# VPAC0_COMMON_0_IVPAC_TOP_0_CFG_SLV_PAR_VPAC_VISS0_S_VBUSP_VISS_FCP_CFA_VBUSP_FLEXCFA register map
Vendor: Texas Instruments
Peripheral module from a debugger description file (folder am62A).
Registers are 32-bit, read-write, reset values left out (the file's numbers can be read two ways) unless marked. A register's access mark holds for its fields unless they carry their own. Offsets are as the file gives them; lines under a group give offsets from that group; [hi:lo] are bit positions; {n}, {i} and the like mark numbered series; 'fields as' and 'values as' point back to an identical list; <NAME> marks a mode.

## VPAC0_COMMON_0_IVPAC_TOP_0_CFG_SLV_PAR_VPAC_VISS0_S_VBUSP_VISS_FCP_CFA_VBUSP_FLEXCFA
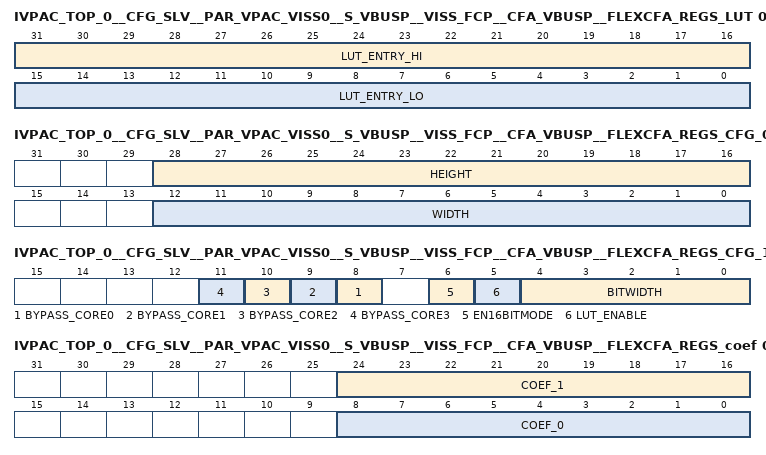
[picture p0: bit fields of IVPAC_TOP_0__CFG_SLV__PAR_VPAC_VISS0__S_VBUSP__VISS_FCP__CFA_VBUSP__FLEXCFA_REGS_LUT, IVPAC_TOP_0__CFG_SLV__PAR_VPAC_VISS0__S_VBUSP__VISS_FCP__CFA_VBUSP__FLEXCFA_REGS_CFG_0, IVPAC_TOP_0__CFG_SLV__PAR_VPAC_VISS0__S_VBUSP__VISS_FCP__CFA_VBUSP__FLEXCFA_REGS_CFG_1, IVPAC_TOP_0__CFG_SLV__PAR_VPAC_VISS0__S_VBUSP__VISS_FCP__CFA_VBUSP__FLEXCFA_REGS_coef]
0x00 IVPAC_TOP_0__CFG_SLV__PAR_VPAC_VISS0__S_VBUSP__VISS_FCP__CFA_VBUSP__FLEXCFA_REGS_LUT — The LUT table contains the information used to reduce the pixle width to 12 from 13-16
  [31:16] LUT_ENTRY_HI — The upper LUT entry n+1.
  [15:0] LUT_ENTRY_LO — The lower LUT entry n+0.
0x1004 IVPAC_TOP_0__CFG_SLV__PAR_VPAC_VISS0__S_VBUSP__VISS_FCP__CFA_VBUSP__FLEXCFA_REGS_CFG_0 — The Control Register controls the input width and height of the module.
  [28:16] HEIGHT — Height of the input image
  [12:0] WIDTH — Width of the input image
0x1008 IVPAC_TOP_0__CFG_SLV__PAR_VPAC_VISS0__S_VBUSP__VISS_FCP__CFA_VBUSP__FLEXCFA_REGS_CFG_1 — The Control Register identifies the bit width of the input image
  [n+8] BYPASS_CORE{n} (n=0..3) — Setting the ~ibypass_core{n} bit will bypass filtering operation, output = input
  [6] EN16BITMODE — 0->legacy mode, 1->Enhanced 16 bit CFA mode, enabled when LUT is disabled
  [5] LUT_ENABLE — 0->Use shift(bitwidth-12) ,1->Use LUT
  [4:0] BITWIDTH — BitWidth of the input image, values greater than 16 will be treated as 16 and values less than 12 will be treated as 12.
0x100C IVPAC_TOP_0__CFG_SLV__PAR_VPAC_VISS0__S_VBUSP__VISS_FCP__CFA_VBUSP__FLEXCFA_REGS_coef — Coefficients for a=core, b=dir, c=phase, d=row, column=e*2+1 and e*2
  [24:16] COEF_1 — Coefficient - e*2+1
  [8:0] COEF_0 — Coefficient - e*2
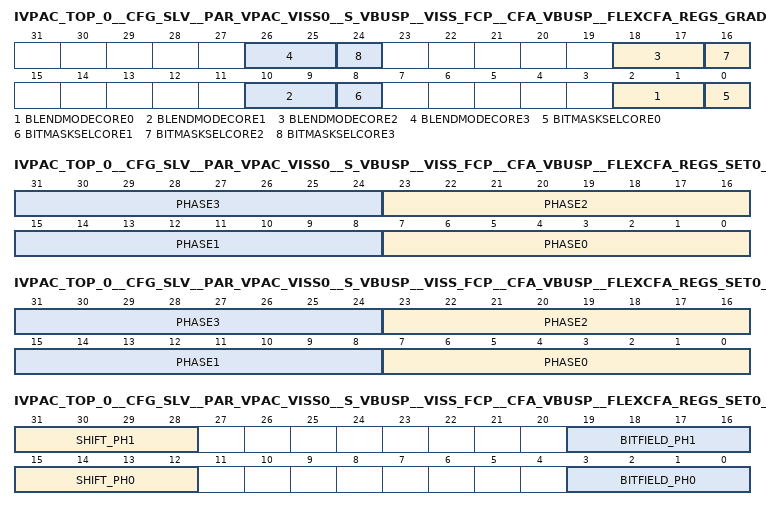
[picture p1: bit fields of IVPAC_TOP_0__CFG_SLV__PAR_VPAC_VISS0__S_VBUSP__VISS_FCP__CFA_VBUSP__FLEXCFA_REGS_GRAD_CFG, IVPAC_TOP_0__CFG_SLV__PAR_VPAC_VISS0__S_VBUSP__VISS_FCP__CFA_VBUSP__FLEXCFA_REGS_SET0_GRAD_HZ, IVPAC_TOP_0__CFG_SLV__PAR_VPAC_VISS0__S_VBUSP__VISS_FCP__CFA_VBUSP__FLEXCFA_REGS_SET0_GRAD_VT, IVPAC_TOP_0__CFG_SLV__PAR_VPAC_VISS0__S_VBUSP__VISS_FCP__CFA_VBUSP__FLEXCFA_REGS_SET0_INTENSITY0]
0x1D8C IVPAC_TOP_0__CFG_SLV__PAR_VPAC_VISS0__S_VBUSP__VISS_FCP__CFA_VBUSP__FLEXCFA_REGS_GRAD_CFG — Gradient configuration for all 4 cores
  [8n+2:8n+1] BLENDMODECORE{n} (n=0..3) — Core-{n} Blend (0:Input-0, 1: Input0/1, 2: Input 0/1/2, 3 : Adaptive Input0/1/2 )
  [8n] BITMASKSELCORE{n} (n=0..3) — Core-{n} Bitmask Select (0: Set-0 , 1: Set-1)
0x1D90 IVPAC_TOP_0__CFG_SLV__PAR_VPAC_VISS0__S_VBUSP__VISS_FCP__CFA_VBUSP__FLEXCFA_REGS_SET0_GRAD_HZ — Gradient Bitfield selector, Set-0 for Horizontal
  [8n+7:8n] PHASE{n} (n=0..3) — Bitfield selector for Phase-{n}
0x1D94 IVPAC_TOP_0__CFG_SLV__PAR_VPAC_VISS0__S_VBUSP__VISS_FCP__CFA_VBUSP__FLEXCFA_REGS_SET0_GRAD_VT — Gradient Bitfield selector, Set-0 for Vertical
  [8n+7:8n] PHASE{n} (n=0..3) — Bitfield selector for Phase-{n}
0x1D98 IVPAC_TOP_0__CFG_SLV__PAR_VPAC_VISS0__S_VBUSP__VISS_FCP__CFA_VBUSP__FLEXCFA_REGS_SET0_INTENSITY0 — Intensity Bitfield selector and shift for phase0/1
  [31:28] SHIFT_PH1 — Intensity shift for Phase-1
  [19:16] BITFIELD_PH1 — Intensity Bitfield selector for Phase-1
  [15:12] SHIFT_PH0 — Intensity shift for Phase-0
  [3:0] BITFIELD_PH0 — Intensity Bitfield selector for Phase-0
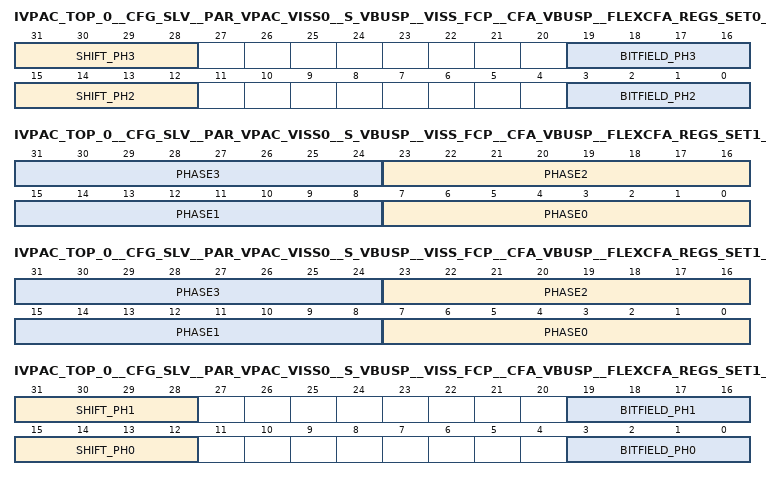
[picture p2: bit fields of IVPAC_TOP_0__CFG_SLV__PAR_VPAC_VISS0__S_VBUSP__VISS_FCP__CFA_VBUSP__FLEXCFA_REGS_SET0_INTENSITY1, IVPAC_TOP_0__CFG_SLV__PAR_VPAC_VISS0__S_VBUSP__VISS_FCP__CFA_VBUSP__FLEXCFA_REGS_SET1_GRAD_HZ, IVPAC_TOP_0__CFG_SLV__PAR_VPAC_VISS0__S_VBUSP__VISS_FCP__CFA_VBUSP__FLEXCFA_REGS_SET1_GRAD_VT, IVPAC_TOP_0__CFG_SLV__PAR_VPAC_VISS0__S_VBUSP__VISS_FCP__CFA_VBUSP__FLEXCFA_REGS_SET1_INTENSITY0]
0x1D9C IVPAC_TOP_0__CFG_SLV__PAR_VPAC_VISS0__S_VBUSP__VISS_FCP__CFA_VBUSP__FLEXCFA_REGS_SET0_INTENSITY1 — Intensity Bitfield selector and shift for phase2/3
  [31:28] SHIFT_PH3 — Intensity shift for Phase-3
  [19:16] BITFIELD_PH3 — Intensity Bitfield selector for Phase-3
  [15:12] SHIFT_PH2 — Intensity shift for Phase-2
  [3:0] BITFIELD_PH2 — Intensity Bitfield selector for Phase-2
0x1DA0 IVPAC_TOP_0__CFG_SLV__PAR_VPAC_VISS0__S_VBUSP__VISS_FCP__CFA_VBUSP__FLEXCFA_REGS_SET1_GRAD_HZ — Gradient Bitfield selector, Set-1 for Horizontal
  [8n+7:8n] PHASE{n} (n=0..3) — Bitfield selector for Phase-{n}
0x1DA4 IVPAC_TOP_0__CFG_SLV__PAR_VPAC_VISS0__S_VBUSP__VISS_FCP__CFA_VBUSP__FLEXCFA_REGS_SET1_GRAD_VT — Gradient Bitfield selector, Set-1 for Vertical
  [8n+7:8n] PHASE{n} (n=0..3) — Bitfield selector for Phase-{n}
0x1DA8 IVPAC_TOP_0__CFG_SLV__PAR_VPAC_VISS0__S_VBUSP__VISS_FCP__CFA_VBUSP__FLEXCFA_REGS_SET1_INTENSITY0 — Intensity Bitfield selector and shift for phase0/1
  fields as IVPAC_TOP_0__CFG_SLV__PAR_VPAC_VISS0__S_VBUSP__VISS_FCP__CFA_VBUSP__FLEXCFA_REGS_SET0_INTENSITY0
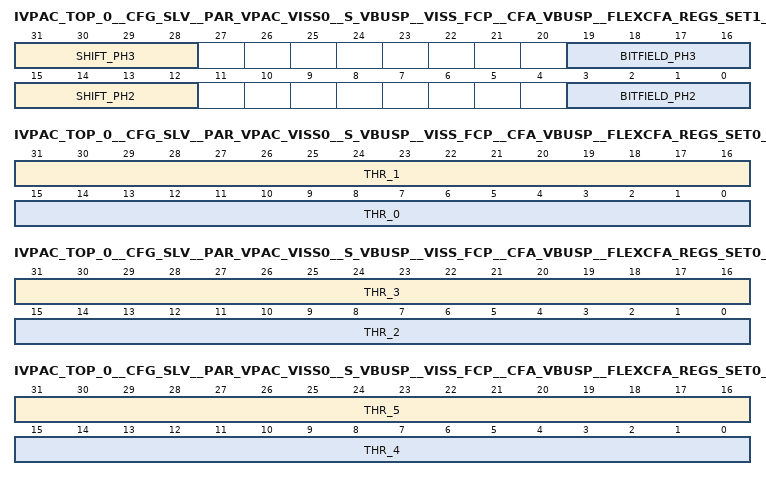
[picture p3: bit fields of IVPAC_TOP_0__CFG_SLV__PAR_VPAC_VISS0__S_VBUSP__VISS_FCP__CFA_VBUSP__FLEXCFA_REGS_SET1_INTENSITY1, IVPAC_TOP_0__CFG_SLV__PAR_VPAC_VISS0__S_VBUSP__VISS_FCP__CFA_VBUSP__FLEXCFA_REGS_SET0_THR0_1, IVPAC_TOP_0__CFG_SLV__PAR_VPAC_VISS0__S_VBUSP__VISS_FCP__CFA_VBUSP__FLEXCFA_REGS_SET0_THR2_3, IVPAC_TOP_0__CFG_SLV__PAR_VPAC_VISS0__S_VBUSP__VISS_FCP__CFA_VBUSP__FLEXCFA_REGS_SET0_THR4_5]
0x1DAC IVPAC_TOP_0__CFG_SLV__PAR_VPAC_VISS0__S_VBUSP__VISS_FCP__CFA_VBUSP__FLEXCFA_REGS_SET1_INTENSITY1 — Intensity Bitfield selector and shift for phase2/3
  fields as IVPAC_TOP_0__CFG_SLV__PAR_VPAC_VISS0__S_VBUSP__VISS_FCP__CFA_VBUSP__FLEXCFA_REGS_SET0_INTENSITY1
0x1DB0 IVPAC_TOP_0__CFG_SLV__PAR_VPAC_VISS0__S_VBUSP__VISS_FCP__CFA_VBUSP__FLEXCFA_REGS_SET0_THR0_1 — Set0 Thr0_1 for H/V Grad difference
  [31:16] THR_1 — H/V Grad diff Threshold_1
  [15:0] THR_0 — H/V Grad diff Threshold_0
0x1DB4 IVPAC_TOP_0__CFG_SLV__PAR_VPAC_VISS0__S_VBUSP__VISS_FCP__CFA_VBUSP__FLEXCFA_REGS_SET0_THR2_3 — Set0 Thr2_3 for H/V Grad difference
  [31:16] THR_3 — H/V Grad diff Threshold_3
  [15:0] THR_2 — H/V Grad diff Threshold_2
0x1DB8 IVPAC_TOP_0__CFG_SLV__PAR_VPAC_VISS0__S_VBUSP__VISS_FCP__CFA_VBUSP__FLEXCFA_REGS_SET0_THR4_5 — Set0 Thr4_5 for H/V Grad difference
  [31:16] THR_5 — H/V Grad diff Threshold_5
  [15:0] THR_4 — H/V Grad diff Threshold_4
0x1DBC IVPAC_TOP_0__CFG_SLV__PAR_VPAC_VISS0__S_VBUSP__VISS_FCP__CFA_VBUSP__FLEXCFA_REGS_SET0_THR6 — Set0 Thr6 for H/V Grad difference
  [15:0] THR_6 — H/V Grad diff Threshold_6
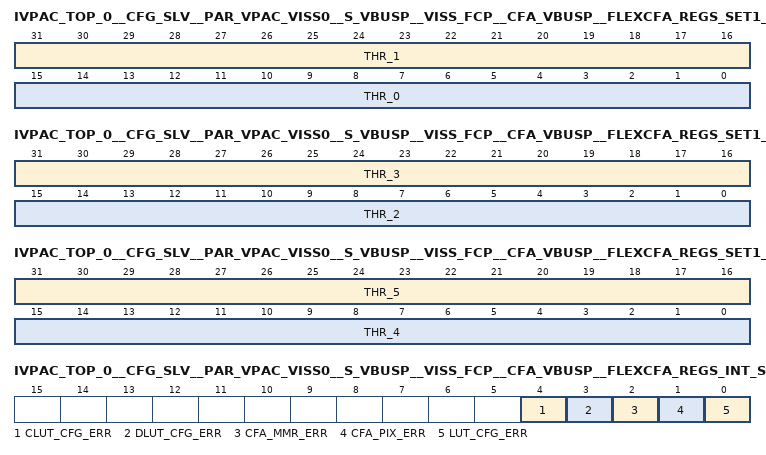
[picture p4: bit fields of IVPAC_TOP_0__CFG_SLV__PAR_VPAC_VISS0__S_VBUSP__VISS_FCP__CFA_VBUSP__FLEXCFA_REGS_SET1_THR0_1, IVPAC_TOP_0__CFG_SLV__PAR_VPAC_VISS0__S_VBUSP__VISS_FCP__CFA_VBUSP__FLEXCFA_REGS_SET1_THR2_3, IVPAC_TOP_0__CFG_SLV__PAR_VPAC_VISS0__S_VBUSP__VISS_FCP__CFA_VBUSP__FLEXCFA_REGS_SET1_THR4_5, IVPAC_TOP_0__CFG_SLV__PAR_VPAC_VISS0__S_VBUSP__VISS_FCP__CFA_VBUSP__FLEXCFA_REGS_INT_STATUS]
0x1DC0 IVPAC_TOP_0__CFG_SLV__PAR_VPAC_VISS0__S_VBUSP__VISS_FCP__CFA_VBUSP__FLEXCFA_REGS_SET1_THR0_1 — Set1 Thr0_1 for H/V Grad difference
  fields as IVPAC_TOP_0__CFG_SLV__PAR_VPAC_VISS0__S_VBUSP__VISS_FCP__CFA_VBUSP__FLEXCFA_REGS_SET0_THR0_1
0x1DC4 IVPAC_TOP_0__CFG_SLV__PAR_VPAC_VISS0__S_VBUSP__VISS_FCP__CFA_VBUSP__FLEXCFA_REGS_SET1_THR2_3 — Set1 Thr2_3 for H/V Grad difference
  fields as IVPAC_TOP_0__CFG_SLV__PAR_VPAC_VISS0__S_VBUSP__VISS_FCP__CFA_VBUSP__FLEXCFA_REGS_SET0_THR2_3
0x1DC8 IVPAC_TOP_0__CFG_SLV__PAR_VPAC_VISS0__S_VBUSP__VISS_FCP__CFA_VBUSP__FLEXCFA_REGS_SET1_THR4_5 — Set1 Thr4_5 for H/V Grad difference
  fields as IVPAC_TOP_0__CFG_SLV__PAR_VPAC_VISS0__S_VBUSP__VISS_FCP__CFA_VBUSP__FLEXCFA_REGS_SET0_THR4_5
0x1DCC IVPAC_TOP_0__CFG_SLV__PAR_VPAC_VISS0__S_VBUSP__VISS_FCP__CFA_VBUSP__FLEXCFA_REGS_SET1_THR6 — Set1 Thr6 for H/V Grad difference
  [15:0] THR_6 — H/V Grad diff Threshold_6
0x1DD0 IVPAC_TOP_0__CFG_SLV__PAR_VPAC_VISS0__S_VBUSP__VISS_FCP__CFA_VBUSP__FLEXCFA_REGS_INT_STATUS access not given — Status/clear register for flexcfa interrupts
  [4] CLUT_CFG_ERR — status/clear for error on CLUT cfg, set when software accesses CLUT during active frame causing potential frame corruption. Write 1 to clear, write 0 has no effect. (access R/W1TC)
  [3] DLUT_CFG_ERR — status/clear for error on DLUT cfg, set when software accesses DLUT during active frame causing potential frame corruption. Write 1 to clear, write 0 has no effect. (access R/W1TC)
  [2] CFA_MMR_ERR — status/clear for error writes to the FIR Filter MMRs during active frame causing potential frame corruption. Write 1 to clear, write 0 has no effect. (access R/W1TC)
  [1] CFA_PIX_ERR — status/clear for error on line array, set when software accesses pixel array during active frame causing potential frame corruption. Write 1 to clear, write 0 has no effect. (access R/W1TC)
  [0] LUT_CFG_ERR — status/clear for error on LUT cfg, set when software accesses LUT during active frame causing potential frame corruption. Write 1 to clear, write 0 has no effect. (access R/W1TC)
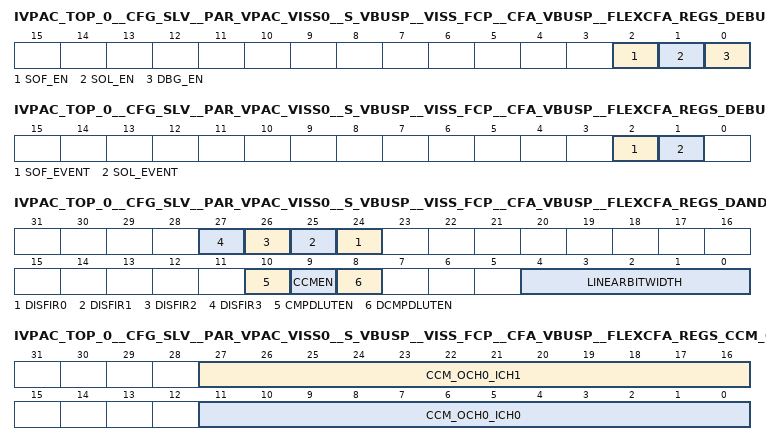
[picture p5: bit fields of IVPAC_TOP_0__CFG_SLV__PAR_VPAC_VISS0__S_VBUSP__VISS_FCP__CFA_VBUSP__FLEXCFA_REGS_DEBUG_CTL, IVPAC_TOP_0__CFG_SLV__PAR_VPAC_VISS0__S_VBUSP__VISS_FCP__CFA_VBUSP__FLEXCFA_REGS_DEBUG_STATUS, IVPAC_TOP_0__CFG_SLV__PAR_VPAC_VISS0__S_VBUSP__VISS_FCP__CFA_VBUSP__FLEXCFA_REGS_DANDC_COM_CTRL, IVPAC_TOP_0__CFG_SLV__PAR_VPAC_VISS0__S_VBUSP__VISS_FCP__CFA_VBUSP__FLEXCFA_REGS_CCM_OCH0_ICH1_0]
0x2000 IVPAC_TOP_0__CFG_SLV__PAR_VPAC_VISS0__S_VBUSP__VISS_FCP__CFA_VBUSP__FLEXCFA_REGS_DEBUG_CTL — Enable for different debug events
  [2] SOF_EN — Enable for sof event
  [1] SOL_EN — Enable for sol event
  [0] DBG_EN — Enable debug features, set to '0' to disable all debug events
0x2004 IVPAC_TOP_0__CFG_SLV__PAR_VPAC_VISS0__S_VBUSP__VISS_FCP__CFA_VBUSP__FLEXCFA_REGS_DEBUG_STATUS access not given — Set/Clear for debug events
  [2] SOF_EVENT — Status/Clear for sof event, write '1' to clear (access R/W1TC)
  [1] SOL_EVENT — Status/Clear for sol event, write '1' to clear (access R/W1TC)
0x2008 IVPAC_TOP_0__CFG_SLV__PAR_VPAC_VISS0__S_VBUSP__VISS_FCP__CFA_VBUSP__FLEXCFA_REGS_LINE_SEL — Selector for which line memory is read or written
  [2:0] LINE_SELECTOR — Selects which line is read or written from the line memory array. The current line is updated at Start-Of-Line, so if the memory is read during a line that is being written, the data for the current_line will contain the new data for this current_line as well as old data from current_line - 5 that has not been overridden yet. If the current_line is the first few lines of a frame, the other lines will be from the end of the previous frame. '0' = current line written, '1' = current line - 1, 2 = current line - 2, 3 = current line - 3, 4 = current line - 4.
0x2010 IVPAC_TOP_0__CFG_SLV__PAR_VPAC_VISS0__S_VBUSP__VISS_FCP__CFA_VBUSP__FLEXCFA_REGS_DANDC_COM_CTRL — This register handles the general conrtrol bits for the DLUT CCM and CLUT blocks that preceed the CC module in the FCP.
  [n+24] DISFIR{n} (n=0..3) — Disables the FIR filter for C{n} to save power
  [10] CMPDLUTEN — Enables the CLUT
  [9] CCMEN — Enables the CCM
  [8] DCMPDLUTEN — Enables the DLUT
  [4:0] LINEARBITWIDTH — Defines the DLUT output bit width the CCM clipping bit width and the CLUT input bit width, valid values are 12-24. Values less than 12, 12 will be used, values greater than 24, 24 will be used. Useful combinations are 12/16/20/24
{0x2040+0x10*i} IVPAC_TOP_0__CFG_SLV__PAR_VPAC_VISS0__S_VBUSP__VISS_FCP__CFA_VBUSP__FLEXCFA_REGS_CCM_OCH{i}_ICH1_0 (i=0..3) — Defines the 12 bit signed S12Q8 wieght for CCM
  [27:16] CCM_OCH{i}_ICH1 — Defines the 12 bit signed wieght for the C{i} output channel from the C1 input channel
  [11:0] CCM_OCH{i}_ICH0 — Defines the 12 bit signed wieght for the C{i} output channel from the C0 input channel
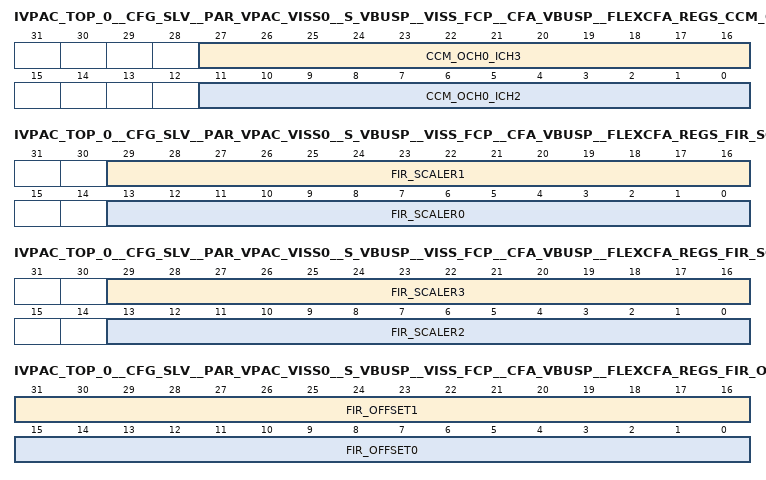
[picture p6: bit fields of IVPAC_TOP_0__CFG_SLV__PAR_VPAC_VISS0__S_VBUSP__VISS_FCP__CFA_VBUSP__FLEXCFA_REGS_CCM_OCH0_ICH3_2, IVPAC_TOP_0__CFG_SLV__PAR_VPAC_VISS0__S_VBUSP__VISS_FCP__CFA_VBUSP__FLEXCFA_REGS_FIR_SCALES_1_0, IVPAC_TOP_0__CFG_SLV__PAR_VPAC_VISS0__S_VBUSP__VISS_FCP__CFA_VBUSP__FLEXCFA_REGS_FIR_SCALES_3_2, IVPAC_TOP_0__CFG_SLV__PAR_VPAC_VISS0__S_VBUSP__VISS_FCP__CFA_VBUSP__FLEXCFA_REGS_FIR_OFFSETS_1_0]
{0x2044+0x10*i} IVPAC_TOP_0__CFG_SLV__PAR_VPAC_VISS0__S_VBUSP__VISS_FCP__CFA_VBUSP__FLEXCFA_REGS_CCM_OCH{i}_ICH3_2 (i=0..3) — Defines the 12 bit signed S12Q8 wieght for CCM
  [27:16] CCM_OCH{i}_ICH3 — Defines the 12 bit signed wieght for the C{i} output channel from the C3 input channel
  [11:0] CCM_OCH{i}_ICH2 — Defines the 12 bit signed wieght for the C{i} output channel from the C2 input channel
{0x2048+0x10*i} IVPAC_TOP_0__CFG_SLV__PAR_VPAC_VISS0__S_VBUSP__VISS_FCP__CFA_VBUSP__FLEXCFA_REGS_CCM_OCH{i}_OFFSET (i=0..3) — Defines the 26 bit signed S26Q24 offset for CCM
  [25:0] CCM_OCH{i}_OFFSET — Defines the 26 bit signed offset for the C{i} output channel
0x2080 IVPAC_TOP_0__CFG_SLV__PAR_VPAC_VISS0__S_VBUSP__VISS_FCP__CFA_VBUSP__FLEXCFA_REGS_FIR_SCALES_1_0 — Defines the FIR output scaler for FIR filters 1 and 0
  [29:16] FIR_SCALER1 — Defines the U14Q8 scaler for FIR filter 1
  [13:0] FIR_SCALER0 — Defines the U14Q8 scaler for FIR filter 0
0x2084 IVPAC_TOP_0__CFG_SLV__PAR_VPAC_VISS0__S_VBUSP__VISS_FCP__CFA_VBUSP__FLEXCFA_REGS_FIR_SCALES_3_2 — Defines the FIR output scaler for FIR filters 3 and 2
  [29:16] FIR_SCALER3 — Defines the U14Q8 scaler for FIR filter 3
  [13:0] FIR_SCALER2 — Defines the U14Q8 scaler for FIR filter 2
0x2088 IVPAC_TOP_0__CFG_SLV__PAR_VPAC_VISS0__S_VBUSP__VISS_FCP__CFA_VBUSP__FLEXCFA_REGS_FIR_OFFSETS_1_0 — Defines the FIR output offset for FIR filters 1 and 0
  [31:16] FIR_OFFSET1 — Defines the U16 offset for FIR filter 1
  [15:0] FIR_OFFSET0 — Defines the U16 offset for FIR filter 0
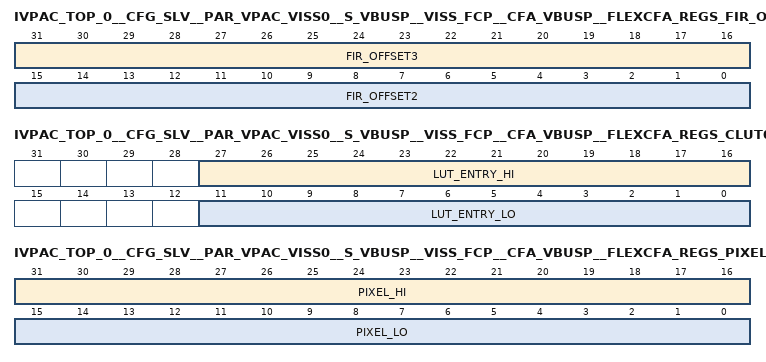
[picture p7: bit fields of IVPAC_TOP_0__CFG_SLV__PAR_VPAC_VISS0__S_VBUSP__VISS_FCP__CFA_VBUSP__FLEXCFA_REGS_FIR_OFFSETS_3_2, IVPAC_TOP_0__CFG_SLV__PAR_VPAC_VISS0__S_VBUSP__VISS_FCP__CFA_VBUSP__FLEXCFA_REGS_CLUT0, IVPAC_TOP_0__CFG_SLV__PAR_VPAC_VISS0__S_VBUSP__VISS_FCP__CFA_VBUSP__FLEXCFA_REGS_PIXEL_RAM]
0x208C IVPAC_TOP_0__CFG_SLV__PAR_VPAC_VISS0__S_VBUSP__VISS_FCP__CFA_VBUSP__FLEXCFA_REGS_FIR_OFFSETS_3_2 — Defines the FIR output offset for FIR filters 3 and 2
  [31:16] FIR_OFFSET3 — Defines the U16 offset for FIR filter 3
  [15:0] FIR_OFFSET2 — Defines the U16 offset for FIR filter 2
{0x2C00+0x500*i} IVPAC_TOP_0__CFG_SLV__PAR_VPAC_VISS0__S_VBUSP__VISS_FCP__CFA_VBUSP__FLEXCFA_REGS_CLUT{i} (i=0..3) — The LUT table contains the information used to reduce the pixle width to 24 from 12
  [27:16] LUT_ENTRY_HI — The upper LUT entry n+1.
  [11:0] LUT_ENTRY_LO — The lower LUT entry n+0.
0x4000 IVPAC_TOP_0__CFG_SLV__PAR_VPAC_VISS0__S_VBUSP__VISS_FCP__CFA_VBUSP__FLEXCFA_REGS_PIXEL_RAM — The pixel RAM contains the array of 16 bit pixels stored and used by the CFA logic. Pixels are 16 bit aligned. Pixels can only be written two at a time.
  [31:16] PIXEL_HI — The 16 bit pixel data for the selected line upper pixel 'n+1'
  [15:0] PIXEL_LO — The 16 bit pixel data for the selected line lower pixel 'n'
